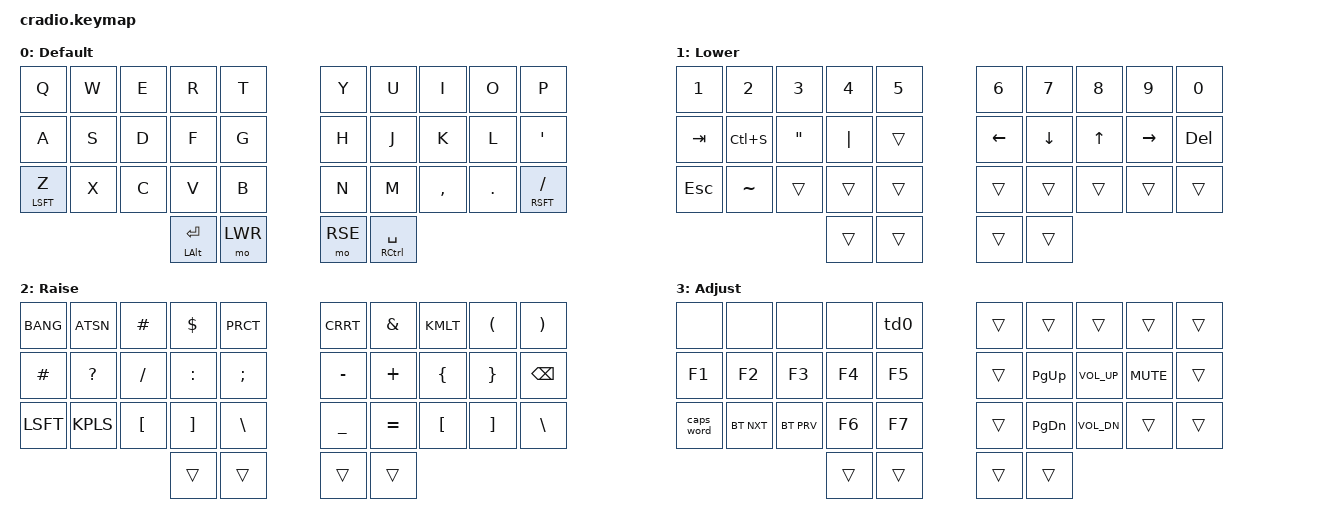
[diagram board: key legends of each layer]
/*
 * Copyright (c) 2020 The ZMK Contributors
 *
 * SPDX-License-Identifier: MIT
 */

#include <behaviors.dtsi>
#include <dt-bindings/zmk/keys.h>
#include <dt-bindings/zmk/bt.h>

#define DEF 0
#define LWR 1
#define RSE 2
#define ADJ 3


&mt {
        // flavor = "tap-preferred";
        // tapping_term_ms = <200>;
};

&caps_word {
    continue-list = <UNDERSCORE MINUS>;
};



/ {
    /* KEY POSITIONS
    -- from https://github.com/caksoylar/zmk-config/blob/main/config/combos.dtsi

    ╭────────────────────╮ ╭────────────────────╮
    │  0   1   2   3   4 │ │  5   6   7   8   9 │
    │ 10  11  12  13  14 │ │ 15  16  17  18  19 │
    │ 20  21  22  23  24 │ │ 25  26  27  28  29 │
    ╰───────────╮ 30  31 │ │ 32  33 ╭───────────╯
                ╰────────╯ ╰────────╯
    */
        combos {
                compatible = "zmk,combos";
                combo_grave {
                        timeout-ms = <50>;
                        key-positions = <0 1>;
                        layers = <DEF>;
                        bindings = <&kp GRAVE>;
                };
                combo_esc {
                        timeout-ms = <50>;
                        key-positions = <0 1>;
                        layers = <LWR RSE>;
                        bindings = <&kp ESC>;
                };
                combo_ctrl_tab {
                        timeout-ms = <50>;
                        key-positions = <10 11>;
                        bindings = <&mt LCTRL TAB>;
                };

                combo_lalt {
                        timeout-ms = <50>;
                        key-positions = <11 12>;
                        bindings = <&kp LALT>;
                };

                combo_lgui {
                        timeout-ms = <50>;
                        key-positions = <12 13>;
                        bindings = <&kp LGUI>;
                };

                combo_ralt {
                        timeout-ms = <50>;
                        key-positions = <17 16>;
                        bindings = <&kp RALT>;
                };
                combo_rgui {
                        timeout-ms = <50>;
                        key-positions = <17 18>;
                        bindings = <&kp RGUI>;
                };
                combo_btclr {
                        timeout-ms = <50>;
                        key-positions = <4 5>;
                        layers = <ADJ>;
                        bindings = <&bt BT_CLR>;
                };
        };

        behaviors {
                // Make it so triple tap is required for destructive functions
                td0: tap_dance_btclr {
                        compatible = "zmk,behavior-tap-dance";
                        label = "TAP_DANCE_BTCLR";
                        #binding-cells = <0>;
                        tapping-term-ms = <200>;
                        bindings = <&none>, <&none>, <&bt BT_CLR>;
                };
        };

        conditional_layers {
                compatible = "zmk,conditional-layers";
                tri_layer {
                        if-layers = <LWR RSE>;
                        then-layer = <ADJ>;
                };
        };

        keymap {
                compatible = "zmk,keymap";
                default_layer {
		        bindings = <
		&kp Q      &kp W  &kp E  &kp R &kp T                 &kp Y  &kp U  &kp I    &kp O   &kp P
                &kp A      &kp S  &kp D  &kp F &kp G                 &kp H  &kp J  &kp K    &kp L   &kp QUOT
                &mt LSFT Z &kp X  &kp C  &kp V &kp B                 &kp N  &kp M  &kp CMMA &kp DOT &mt RSFT FSLH
                                    &mt LALT RET &mo LWR           &mo RSE &mt RCTRL SPC
                                >;
                        label = "Default";
                };

                lower_layer {
                        bindings = <
                &kp NUM_1 &kp NUM_2 &kp NUM_3    &kp NUM_4  &kp NUM_5            &kp NUM_6 &kp NUM_7 &kp NUM_8 &kp NUM_9 &kp NUM_0
                &kp TAB   &kp LC(S) &kp DQT      &kp PIPE   &trans               &kp LEFT  &kp DOWN  &kp UP    &kp RIGHT &kp DEL
                &kp ESC   &kp TILDE &trans       &trans     &trans               &trans    &trans    &trans    &trans    &trans
                                                     &trans &trans               &trans &trans
                >;
                        label = "Lower";
                };

                raise_layer {
                        bindings = <
                &kp BANG  &kp ATSN   &kp HASH  &kp DLLR  &kp PRCT        &kp CRRT  &kp AMPS &kp KMLT &kp LPRN &kp RPRN
                &kp HASH  &kp QMARK  &kp FSLH  &kp COLN  &kp SCLN        &kp MINUS &kp PLUS &kp LBRC &kp RBRC &kp BKSP
                &kp LSFT  &kp KPLS   &kp LBKT  &kp RBKT  &kp BSLH        &kp UNDER &kp EQUAL&kp LBKT &kp RBKT &kp BSLH
                                                 &trans  &trans          &trans &trans
                                >;
                        label = "Raise";
                };

                adjust_layer {
                        bindings = <
                &none      &none      &none      &none     &td0          &trans &trans     &trans        &trans     &trans
                &kp F1     &kp F2     &kp F3     &kp F4    &kp F5        &trans &kp PG_UP  &kp K_VOL_UP  &kp K_MUTE &trans
                &caps_word &bt BT_NXT &bt BT_PRV &kp F6    &kp F7        &trans &kp PG_DN  &kp K_VOL_DN  &trans     &trans
                                                    &trans &trans        &trans &trans
                >;
                        label = "Adjust";
                };
        };
};
